# STM32H503 register map
File version: 1.5
CPU: CM33 r0p0, little endian, MPU, FPU, 4 interrupt priority bits
Registers are 32-bit, read-write, reset 0x0 unless marked. A register's access mark holds for its fields unless they carry their own. Offsets are from the block's base; [hi:lo] are bit positions; {n}, {i} and the like mark numbered series.

## RNG — True random number generator
Base 0x420C0800
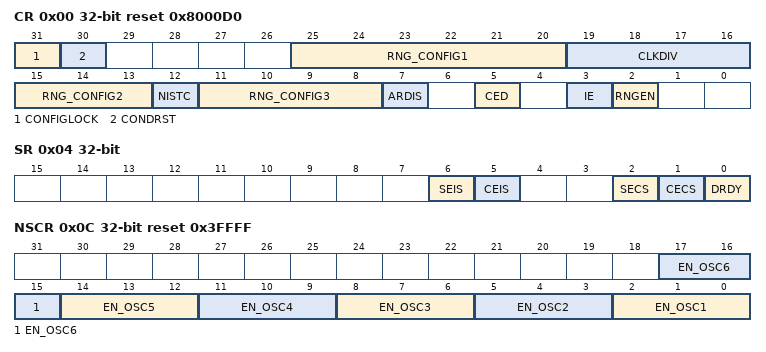
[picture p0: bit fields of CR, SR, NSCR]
0x00 CR reset 0x8000D0 — RNG control register
  [31] CONFIGLOCK — RNG Config lock This bitfield is set once: if this bit is set it can only be reset to 0 if RNG is reset.
    0=Enabled (Writes to the RNG_CR configuration bits [29:4] are allowed); 1=Disabled (Writes to the RNG_CR configuration bits [29:4] are ignored until the next RNG reset)
  [30] CONDRST — Conditioning soft reset Write 1 and then write 0 to reset the conditioning logic, clear all the FIFOs and start a new RNG initialization process, with RNG_SR cleared. Registers RNG_CR and RNG_NSCR are not changed by CONDRST. This bit must be set to 1 in the same access that set any configuration bits [29:4]. In other words, when CONDRST bit is set to 1 correct configuration in bits [29:4] must also be written. When CONDRST is set to 0 by software its value goes to 0 when the reset process is done. It takes about 2 AHB clock cycles + 2 RNG clock cycles.
  [25:20] RNG_CONFIG1 — RNG configuration 1 Reserved to the RNG configuration (bitfield 1). Must be initialized using the recommended value documented in Section 23.6: RNG entropy source validation. Writing any bit of RNG_CONFIG1 is taken into account only if CONDRST bit is set to 1 in the same access, while CONFIGLOCK remains at 0. Writing to this bit is ignored if CONFIGLOCK = 1.
    15=ConfigA (Recommended value for config A (NIST certifiable)); 24=ConfigB (Recommended value for config B (not NIST certifiable))
  [19:16] CLKDIV — Clock divider factor This value used to configure an internal programmable divider (from 1 to 16) acting on the incoming RNG clock. These bits can be written only when the core is disabled (RNGEN = 0). ... Writing these bits is taken into account only if CONDRST bit is set to 1 in the same access, while CONFIGLOCK remains at 0. Writing to this bit is ignored if CONFIGLOCK = 1.
    0=Div1 (Internal RNG clock after divider is similar to incoming RNG clock); 1=Div2 (Divide RNG clock by 2^1); 2=Div4 (Divide RNG clock by 2^2); 3=Div8 (Divide RNG clock by 2^3); 4=Div16 (Divide RNG clock by 2^4); 5=Div32 (Divide RNG clock by 2^5); 6=Div64 (Divide RNG clock by 2^6); 7=Div128 (Divide RNG clock by 2^7); 8=Div256 (Divide RNG clock by 2^8); 9=Div512 (Divide RNG clock by 2^9); 10=Div1024 (Divide RNG clock by 2^10); 11=Div2048 (Divide RNG clock by 2^11); 12=Div4096 (Divide RNG clock by 2^12); 13=Div8192 (Divide RNG clock by 2^13); 14=Div16384 (Divide RNG clock by 2^14); 15=Div32768 (Divide RNG clock by 2^15)
  [15:13] RNG_CONFIG2 — RNG configuration 2 Reserved to the RNG configuration (bitfield 2). Refer to RNG_CONFIG1 bitfield for details.
    0=ConfigA_B (Recommended value for config A and B)
  [12] NISTC — Non NIST compliant two conditioning loops are performed and 256 bits of noise source are used. Writing this bit is taken into account only if CONDRST bit is set to 1 in the same access, while CONFIGLOCK remains at 0. Writing to this bit is ignored if CONFIGLOCK = 1.
    0=Default (Hardware default values for NIST compliant RNG. In this configuration per 128-bit output two conditioning loops are performed and 256 bits of noise source are used); 1=Custom values for NIST compliant RNG
  [11:8] RNG_CONFIG3 — RNG configuration 3 Reserved to the RNG configuration (bitfield 3). Refer to RNG_CONFIG1 bitfield for details. If NISTC bit is cleared in this register RNG_CONFIG3 bitfield values are ignored by RNG.
    0=ConfigB (Recommended value for config B (not NIST certifiable)); 13=ConfigA (Recommended value for config A (NIST certifiable))
  [7] ARDIS — Auto reset disable When auto-reset is enabled application still need to clear SEIS bit after a noise source error. Writing this bit is taken into account only if CONDRST bit is set to 1 in the same access, while CONFIGLOCK remains at 0. Writing to this bit is ignored if CONFIGLOCK = 1.
  [5] CED — Clock error detection The clock error detection cannot be enabled nor disabled on-the-fly when the RNG is enabled, i.e. to enable or disable CED the RNG must be disabled. Writing this bit is taken into account only if CONDRST bit is set to 1 in the same access, while CONFIGLOCK remains at 0. Writing to this bit is ignored if CONFIGLOCK = 1.
    0=Enabled (Clock error detection is enabled); 1=Disabled (Clock error detection is disabled)
  [3] IE — Interrupt Enable
    0=Disabled (RNG interrupt is disabled); 1=Enabled (RNG interrupt is enabled)
  [2] RNGEN — True random number generator enable
    0=Disabled (Random number generator is disabled); 1=Enabled (Random number generator is enabled)
0x04 SR access per field — RNG status register
  [6] SEIS rw write-0-clears — Seed error interrupt status This bit is set at the same time as SECS. It is cleared by writing 0 (unless CONDRST is used). Writing 1 has no effect. An interrupt is pending if IE = 1 in the RNG_CR register.
    on write: 0=Clear flag | on read: 0=No faulty sequence detected; 1=Fault (At least one faulty sequence has been detected. See **SECS** bit description for details. An interrupt is pending if IE = 1 in the RNG_CR register.)
  [5] CEIS rw write-0-clears — Clock error interrupt status This bit is set at the same time as CECS. It is cleared by writing 0. Writing 1 has no effect. An interrupt is pending if IE = 1 in the RNG_CR register.
    on write: 0=Clear flag | on read: 0=Correct (The RNG clock is correct); 1=Slow (The RNG has been detected too slow An interrupt is pending if IE = 1 in the RNG_CR register)
  [2] SECS ro — Seed error current status Run-time repetition count test failed (noise source has provided more than 24 consecutive bits at a constant value 0 or 1, or more than 32 consecutive occurrence of two bits patterns 01 or 10) Start-up or continuous adaptive proportion test on noise source failed. Start-up post-processing/conditioning sanity check failed.
    0=No faulty sequence has currently been detected. If the SEIS bit is set, this means that a faulty sequence was detected and the situation has been recovered.; 1=Fault (At least one faulty sequence has been detected - see ref manual for details)
  [1] CECS ro — Clock error current status Note: CECS bit is valid only if the CED bit in the RNG_CR register is set to 0.
    0=Correct (The RNG clock is correct. If the CEIS bit is set, this means that a slow clock was detected and the situation has been recovered.); 1=Slow (The RNG clock is too slow)
  [0] DRDY ro — Data Ready Once the output buffer becomes empty (after reading the RNG_DR register), this bit returns to 0 until a new random value is generated. Note: The DRDY bit can rise when the peripheral is disabled (RNGEN = 0 in the RNG_CR register). If IE=1 in the RNG_CR register, an interrupt is generated when DRDY = 1.
    0=Invalid (The RNG_DR register is not yet valid, no random data is available); 1=Valid (The RNG_DR register contains valid random data. Once the RNG_DR register has been read, this bit returns to 0 until a new random value is generated.)
0x08 DR ro — RNG data register
  [31:0] RNDATA — Random data 32-bit random data which are valid when DRDY = 1. When DRDY = 0 RNDATA value is zero. It is recommended to always verify that RNG_DR is different from zero. Because when it is the case a seed error occurred between RNG_SR polling and RND_DR output reading (rare event).
0x0C NSCR access not given reset 0x3FFFF — RNG noise source control register
  [3n-1:3n-3] EN_OSC{n} (n=1..6) — Each bit drives one oscillator enable signal input of instance number {n}, gated with the RNGEN bit in RNG_CR (set bit to enable the oscillator).
0x10 HTCR reset 0x72AC — RNG health test control register
  [31:0] HTCFG — health test configuration This configuration is used by RNG to configure the health tests. See Section 23.6: RNG entropy source validation for the recommended value. Note: The RNG behavior, including the read to this register, is not guaranteed if a different value from the recommended value is written.
    0xAA74=Recommended value for RNG certification (0x0000_AA74); 0x17590ABC=Magic number to be written before any write (0x1759_0ABC)
